# D1H register map
Vendor: Allwinner; File version: 1.0
Allwinner's D1-H chip unofficial SVD file maintained by community
Registers are 32-bit, read-write, reset 0x0 unless marked. A register's access mark holds for its fields unless they carry their own. Offsets are from the block's base; lines under a group give offsets from that group; [hi:lo] are bit positions; {n}, {i} and the like mark numbered series; 'fields as' and 'values as' point back to an identical list; <NAME> marks a mode.

## Memory map
0x01701000 DSP_MSGBOX size 0x1000 — DSP Message Box
0x02000000 GPIO size 0x800 — Gerneral Purpose Input/Output
0x02000C00 PWM size 0x400 — Pulse Width Modulation
0x02001000 CCU size 0x10000 — Clock Controller Unit
0x02003000 CIR_TX size 0x400 — Counsumer Infrared Transmitter
0x02008000 LEDC size 0x400
0x02009000 GPADC size 0x400 — General Purpose ADC
0x02009400 THC size 0x400 — Thermal Sensor Controller
0x02009800 LRADC size 0x400 — Low Rate ADC
0x02009C00 TPADC size 0x400 — Touch Panel ADC
0x02010000 IOMMU size 0x10000 — I/O Memory Management Unit
0x02030000 AudioCodec size 0x1000
0x02031000 DMIC size 0x400
{0x2032000+0x1000*n} I2S_PCM[{n}] (n=0..2) size 0x1000 — I2S/PCM
0x02036000 OWA size 0x400 — One Wire Audio
0x02050000 TIMER size 0x1000 — Timer Module, includes timer0, timer1, watchdog and audio video synchronization
{0x2500000+0x400*n} UART[{n}] (n=0..5) size 0x400 — Universal Asynchronous Receiver Transmitter
{0x2502000+0x400*n} TWI[{n}] (n=0..3) size 0x400 — Two Wire Interface
0x03000000 SYS_CFG size 0x1000 — System Configuration
0x03002000 DMAC size 0x1000 — Direct Memory Access Controller
0x03005000 Spinlock size 0x1000
0x03008000 HSTimer size 0x1000 — High Speed Timer
0x03040000 CE_NS size 0x800 — Crypoto Engine
{0x4020000+0x1000*n} SMHC[{n}] (n=0..2) size 0x1000 — SD/MMC Host Controller
0x04025000 SPI0 size 0x1000 — Serial Peripheral Interface
0x04026000 SPI_DBI size 0x1000 — Serial Peripheral Interface Display Bus Interface
0x04100000 USB0 size 0x100000 — USB2.0 DRD
0x04200000 USB1 size 0x100000 — USB2.0 HOST
0x04500000 EMAC size 0x10000 — Ethernet Medium Access Controller
0x05461000 TCON_LCD0 size 0x1000 — Timing COntroller LCD
0x05470000 TCON_TV0 size 0x1000 — Timing COntroller TV
0x05600000 TVE_TOP size 0x4000 — TV Encoder TOP
0x05604000 TVE size 0x4000 — TV Encoder
0x05800000 CSIC size 0x400000 — CMOS Sensor Interface Controller
0x05C00000 TVD_TOP size 0x1000 — Television Decoder TOP
0x05C01000 TVD0 size 0x1000 — Television Decoder
0x06010000 RISCV_CFG size 0x1000 — RISC-V System Configuration
0x0601F000 RISC_V_MSGBOX size 0x1000 — RISC-V Message Box
0x07040000 CIR_RX size 0x400 — Counsumer Infrared Receiver
0x07090000 RTC size 0x1000 — Real Time CLock
0x10000000 PLIC — Platform Level Interrupt Control
0x14000000 CLINT size 0x10000 — Core-Local Interruptor

## Interrupts
18 UART0 (UART[{n}])
19 UART1 (UART[{n}])
20 UART2 (UART[{n}])
21 UART3 (UART[{n}])
22 UART4 (UART[{n}])
23 UART5 (UART[{n}])
25 TWI0 (TWI[{n}])
26 TWI1 (TWI[{n}])
27 TWI2 (TWI[{n}])
28 TWI3 (TWI[{n}])
31 SPI0
32 SPI1 (SPI_DBI)
34 PWM
35 IR_TX (CIR_TX)
36 LEDC
39 OWA
40 DMIC
41 AUDIO_CODEC (AudioCodec)
42 I2S_PCM0 (I2S_PCM[{n}])
43 I2S_PCM1 (I2S_PCM[{n}])
44 I2S_PCM2 (I2S_PCM[{n}])
45 USB0_DEVICE (USB0)
46 USB0_EHCI (USB0)
47 USB0_OHCI (USB0)
49 USB1_EHCI (USB1)
50 USB1_OHCI (USB1)
56 SMHC0 (SMHC[{n}])
57 SMHC1 (SMHC[{n}])
58 SMHC2 (SMHC[{n}])
62 EMAC
66 DMAC_NS (DMAC)
68 CE_NS
70 SPINLOCK (Spinlock)
71 HSTIMER0 (HSTimer)
72 HSTIMER1 (HSTimer)
73 GPADC
74 THS (THC)
75 TIMER0 (TIMER)
76 TIMER1 (TIMER)
77 LRADC
78 TPADC
79 WATCHDOG (TIMER)
80 IOMMU
85 GPIOB_NS (GPIO)
87 GPIOC_NS (GPIO)
89 GPIOD_NS (GPIO)
91 GPIOE_NS (GPIO)
93 GPIOF_NS (GPIO)
111 CSI_DMA0 (CSIC)
112 CSI_DMA1 (CSIC)
122 CSI_TOP_PKT (CSIC)
123 TVD (TVD_TOP)
144 RISC-V_MBOX_RISC-V (RISC_V_MSGBOX)
145 RISC-V_MBOX_DSP (RISC_V_MSGBOX)
167 IR_RX (CIR_RX)

## SYS_CFG — System Configuration
Base 0x03000000
0x08 DSP_BOOT_RAMMAP — DSP Boot SRAM Remap Control Register
  [0] DSP_BOOT_SRAM_REMAP_ENABLE
    0=DSP_SYS; 1=SYS_BOOT
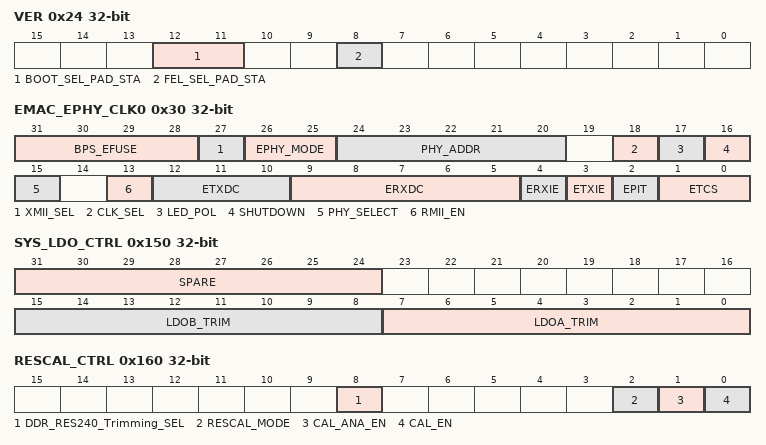
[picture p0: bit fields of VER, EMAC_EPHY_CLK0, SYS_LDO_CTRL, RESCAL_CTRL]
0x24 VER ro — Version Register
  [12:11] BOOT_SEL_PAD_STA
  [8] FEL_SEL_PAD_STA — Fel Select Pin Status
    0=RUN_FEL; 1=TRY_MEDIA_BOOT
0x30 EMAC_EPHY_CLK0 — EMAC-EPHY Clock Register 0
  [31:28] BPS_EFUSE
  [27] XMII_SEL
    0=Internal; 1=External
  [26:25] EPHY_MODE
    0=Normal; 1=Simulation; 2=AFE_Test
  [24:20] PHY_ADDR
  [18] CLK_SEL
    0=F25M; 1=F24M
  [17] LED_POL
    0=High; 1=Low
  [16] SHUTDOWN
    0=Power_up; 1=Shut_down
  [15] PHY_SELECT
    0=External; 1=Internal
  [13] RMII_EN
    0=Disable; 1=Enable
  [12:10] ETXDC
  [9:5] ERXDC
  [4] ERXIE
    0=Disable; 1=Enable
  [3] ETXIE
    0=Disable; 1=Enable
  [2] EPIT
    0=MII; 1=RGMII
  [1:0] ETCS
    0=MII; 1=External_GMII_RGMII; 2=Internal_GMII_RGMII
0x150 SYS_LDO_CTRL — System LDO Control Register
  [31:24] SPARE
  [15:8] LDOB_TRIM
    0=O1_167; 1=O1_18; 2=O1_193; 3=O1_207; 4=O1_22; 5=O1_233; 6=O1_247; 7=O1_260; 8=O1_273; 9=O1_287; 10=O1_3; 11=O1_313; 12=O1_327; 13=O1_340; 14=O1_353; 15=O1_367; 16=O1_38; 17=O1_393; 18=O1_407; 19=O1_42; 20=O1_433; 21=O1_447; 22=O1_46; 23=O1_473; 24=O1_487; 25=O1_5; 26=O1_513; 27=O1_527; 28=O1_54; 29=O1_553; 30=O1_567; 31=O1_58; 32=O1_593; 33=O1_607; 34=O1_627; 35=O1_64; 36=O1_653; 37=O1_667; 38=O1_680; 39=O1_693; 40=O1_707; 41=O1_720; 42=O1_733; 43=O1_747; 44=O1_76; 45=O1_773; 46=O1_787; 47=O1_8; 48=O1_813; 49=O1_827; 50=O1_84; 51=O1_853; 52=O1_867; 53=O1_88; 54=O1_893; 55=O1_907; 56=O1_92; 57=O1_933; 58=O1_947; 59=O1_96; 60=O1_973; 61=O1_987; 62=O2; 63=O2_013
  [7:0] LDOA_TRIM
    0=O1_593; 1=O1_607; 2=O1_627; 3=O1_64; 4=O1_653; 5=O1_667; 6=O1_680; 7=O1_693; 8=O1_707; 9=O1_720; 10=O1_733; 11=O1_747; 12=O1_76; 13=O1_773; 14=O1_787; 15=O1_8; 16=O1_813; 17=O1_827; 18=O1_84; 19=O1_853; 20=O1_867; 21=O1_88; 22=O1_893; 23=O1_907; 24=O1_92; 25=O1_933; 26=O1_947; 27=O1_96; 28=O1_973; 29=O1_987; 30=O2; 31=O2_013
0x160 RESCAL_CTRL — Resistor Calibration Control Register
  [8] DDR_RES240_Trimming_SEL — 240ohms Resistor Trimming Source Select
    0=RESCAL; 1=RES240_TRIM
  [2] RESCAL_MODE — RESCAL Calibration Mode Select
    0=Auto_Calibration
  [1] CAL_ANA_EN — Calibration Circuits Analog Enable
    0=Disable; 1=Enable
  [0] CAL_EN — Auto Calibration Enable
    0=Disable; 1=Enable
0x168 RES240_CTRL — 240ohms Resistor Manual Control Register
  [5:0] DDR_RES240_TRIM — 240ohms Resistor trimming bit
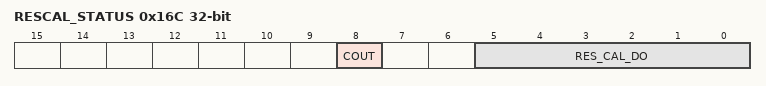
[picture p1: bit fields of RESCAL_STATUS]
0x16C RESCAL_STATUS ro — Resistor Calibration Status Register
  [8] COUT — Calibration Circuits Analog COmpare Output
  [5:0] RES_CAL_DO — RESCAL Calibration Results Output
